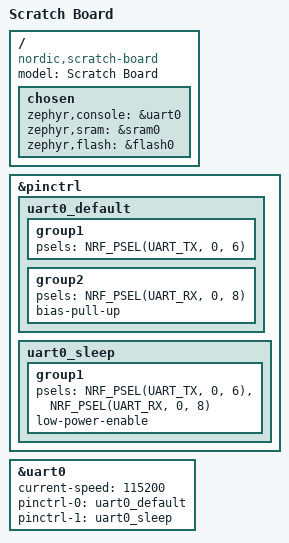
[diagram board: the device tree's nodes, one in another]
/dts-v1/;
#include <nordic/nrf52840_qiaa.dtsi>

/ {
	model = "Scratch Board";
	compatible = "nordic,scratch-board";

	chosen {
		zephyr,console = &uart0;
		zephyr,sram = &sram0;
		zephyr,flash = &flash0;
	};
};

&pinctrl {
	uart0_default: uart0_default {
		group1 {
			psels = <NRF_PSEL(UART_TX, 0, 6)>;
		};
		group2 {
			psels = <NRF_PSEL(UART_RX, 0, 8)>;
			bias-pull-up;
		};
	};

	uart0_sleep: uart0_sleep {
		group1 {
			psels = <NRF_PSEL(UART_TX, 0, 6)>,
				<NRF_PSEL(UART_RX, 0, 8)>;
			low-power-enable;
		};
	};
};

&uart0 {
	status = "okay";
	current-speed = <115200>;
	pinctrl-0 = <&uart0_default>;
	pinctrl-1 = <&uart0_sleep>;
	pinctrl-names = "default", "sleep";
};
